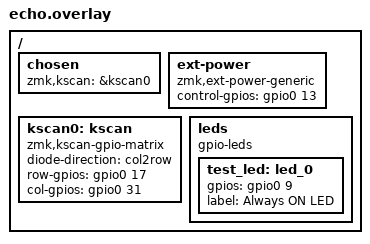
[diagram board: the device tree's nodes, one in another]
/ {
    chosen {
        zmk,kscan = &kscan0;
    };

    // 强制让 P1.06 所在的 GPIO 组上电
    ext-power {
        compatible = "zmk,ext-power-generic";
        control-gpios = <&gpio0 13 GPIO_ACTIVE_HIGH>; // 假设 P0.13 是电源使能脚
    };

    kscan0: kscan {
        compatible = "zmk,kscan-gpio-matrix";
        diode-direction = "col2row";
        // 这里暂时只写两个引脚测试，减少干扰
        row-gpios = <&gpio0 17 (GPIO_ACTIVE_HIGH | GPIO_PULL_DOWN)>;
        col-gpios = <&gpio0 31 GPIO_ACTIVE_HIGH>;
    };

    // 强制输出高电平
    leds {
        compatible = "gpio-leds";
        test_led: led_0 {
            gpios = <&gpio0 9 GPIO_ACTIVE_HIGH>; // P1.06
            label = "Always ON LED";
        };
    };
};
